# STM32F413 register map
File version: 1.9
CPU: CM4 r0p1, little endian, MPU, FPU, 4 interrupt priority bits
Registers are 32-bit, read-write, reset 0x0 unless marked. A register's access mark holds for its fields unless they carry their own. Offsets are from the block's base; [hi:lo] are bit positions; {n}, {i} and the like mark numbered series.

## EXTI — External interrupt/event controller
Base 0x40013C00
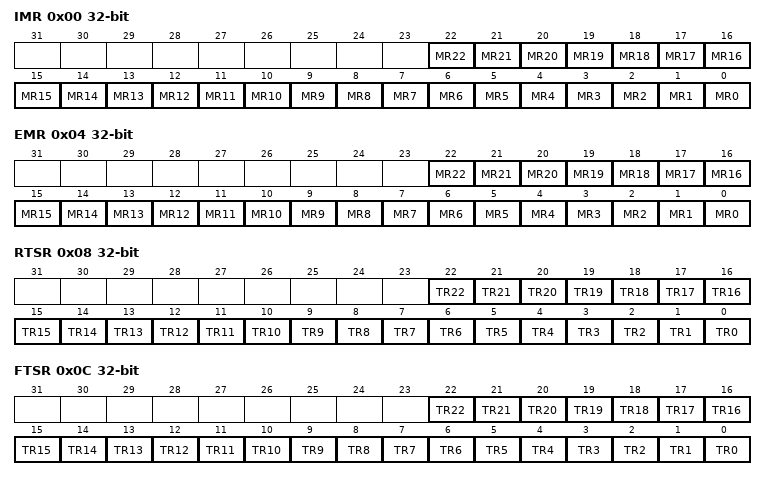
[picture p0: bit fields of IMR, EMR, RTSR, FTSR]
0x00 IMR — Interrupt mask register (EXTI_IMR)
  [n] MR{n} (n=0..22) — Interrupt Mask on line {n}
0x04 EMR — Event mask register (EXTI_EMR)
  [n] MR{n} (n=0..22) — Event Mask on line {n}
0x08 RTSR — Rising Trigger selection register (EXTI_RTSR)
  [n] TR{n} (n=0..22) — Rising trigger event configuration of line {n}
0x0C FTSR — Falling Trigger selection register (EXTI_FTSR)
  [n] TR{n} (n=0..22) — Falling trigger event configuration of line {n}
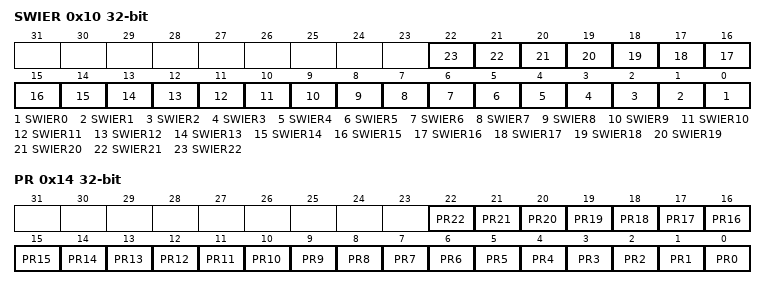
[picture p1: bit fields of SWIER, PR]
0x10 SWIER — Software interrupt event register (EXTI_SWIER)
  [n] SWIER{n} (n=0..22) — Software Interrupt on line {n}
0x14 PR — Pending register (EXTI_PR)
  [22] PR22 write-1-clears — Pending bit 22
  [21] PR21 write-1-clears — Pending bit 21
  [20] PR20 — Pending bit 20
  [19] PR19 — Pending bit 19
  [n] PR{n} write-1-clears (n=0..18) — Pending bit {n}

## FMPI2C — fast-mode Inter-integrated circuit
Base 0x40006000
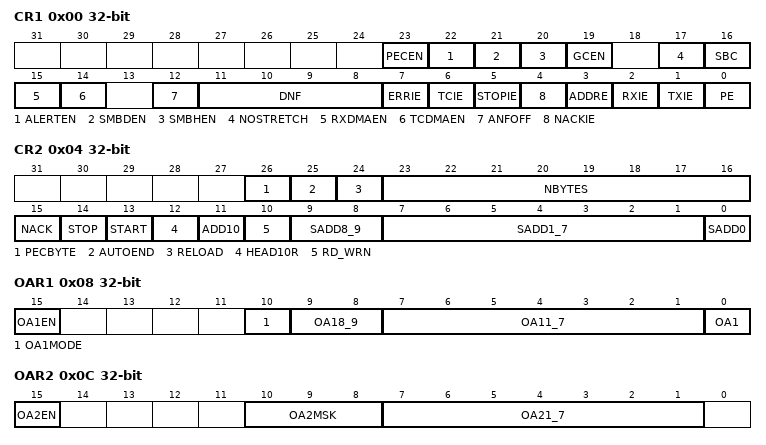
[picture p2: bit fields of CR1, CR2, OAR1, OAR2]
0x00 CR1 — Control register 1
  [23] PECEN
  [22] ALERTEN
  [21] SMBDEN
  [20] SMBHEN
  [19] GCEN
  [17] NOSTRETCH
  [16] SBC
  [15] RXDMAEN
  [14] TCDMAEN
  [12] ANFOFF
  [11:8] DNF
  [7] ERRIE
  [6] TCIE
  [5] STOPIE
  [4] NACKIE
  [3] ADDRE
  [2] RXIE
  [1] TXIE
  [0] PE — Peripheral enable
0x04 CR2 — Control register 2
  [26] PECBYTE — Packet error checking byte
  [25] AUTOEND — Automatic end mode
  [24] RELOAD — NBYTES reload mode
  [23:16] NBYTES — Number of bytes
  [15] NACK — NACK generation
  [14] STOP — Stop generation
  [13] START — Start generation
  [12] HEAD10R — 10-bit address header only read direction
  [11] ADD10 — 10-bit addressing mode
  [10] RD_WRN — Transfer direction
  [9:8] SADD8_9 — Slave address bit 8_9
  [7:1] SADD1_7 — Slave address bit 7_1
  [0] SADD0 — Slave address bit 0
0x08 OAR1 — Own address register 1
  [15] OA1EN, [10] OA1MODE, [9:8] OA18_9, [7:1] OA11_7, [0] OA1
0x0C OAR2 — Own address register 2
  [15] OA2EN, [10:8] OA2MSK, [7:1] OA21_7
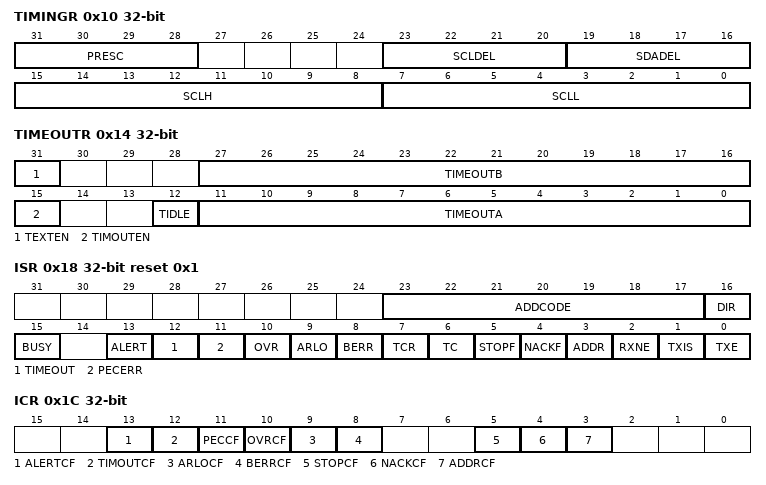
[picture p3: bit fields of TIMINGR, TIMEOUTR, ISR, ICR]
0x10 TIMINGR — Timing register
  [31:28] PRESC, [23:20] SCLDEL, [19:16] SDADEL, [15:8] SCLH, [7:0] SCLL
0x14 TIMEOUTR — Timeout register
  [31] TEXTEN, [27:16] TIMEOUTB, [15] TIMOUTEN, [12] TIDLE, [11:0] TIMEOUTA
0x18 ISR access per field reset 0x1 — Interrupt and Status register
  [23:17] ADDCODE ro, [16] DIR ro, [15] BUSY ro, [13] ALERT ro, [12] TIMEOUT ro, [11] PECERR ro, [10] OVR ro, [9] ARLO ro, [8] BERR ro, [7] TCR ro, [6] TC ro, [5] STOPF ro, [4] NACKF ro, [3] ADDR ro, [2] RXNE ro, [1] TXIS rw, [0] TXE rw
0x1C ICR wo — Interrupt clear register
  [13] ALERTCF — Alert flag clear
  [12] TIMOUTCF — Timeout detection flag clear
  [11] PECCF — PEC Error flag clear
  [10] OVRCF — Overrun/Underrun flag clear
  [9] ARLOCF — Arbitration Lost flag clear
  [8] BERRCF — Bus error flag clear
  [5] STOPCF — Stop detection flag clear
  [4] NACKCF — Not Acknowledge flag clear
  [3] ADDRCF — Address matched flag clear
0x20 PECR ro — PEC register
  [7:0] PEC
0x24 RXDR ro — Receive data register
  [7:0] RXDATA
0x28 TXDR — Transmit data register
  [7:0] TXDATA

## FLASH
Base 0x40023C00
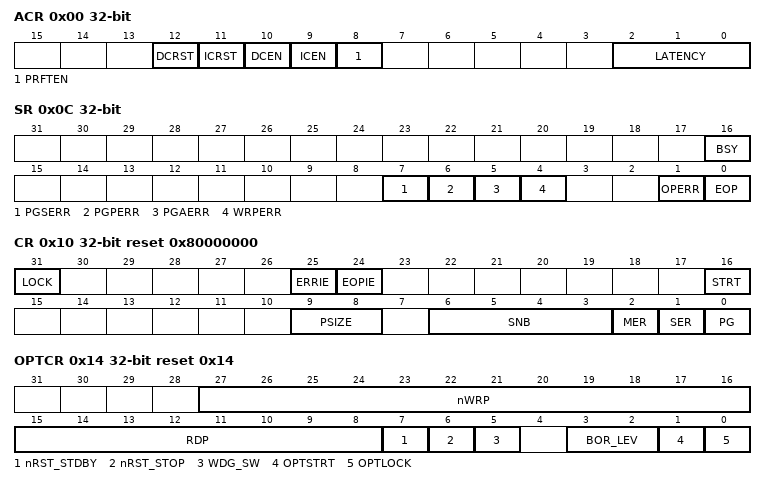
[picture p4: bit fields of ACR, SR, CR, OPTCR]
0x00 ACR access per field — Flash access control register
  [12] DCRST rw — Data cache reset
  [11] ICRST wo write-1-sets — Instruction cache reset
  [10] DCEN rw — Data cache enable
  [9] ICEN rw — Instruction cache enable
  [8] PRFTEN rw — Prefetch enable
  [2:0] LATENCY rw
0x04 KEYR wo — Flash key register
  [31:0] KEY — FPEC key
0x08 OPTKEYR wo — Flash option key register
  [31:0] OPTKEY — Option byte key
0x0C SR access per field — Status register
  [16] BSY ro — Busy
  [7] PGSERR rw write-1-clears — Programming sequence error
  [6] PGPERR rw write-1-clears — Programming parallelism error
  [5] PGAERR rw write-1-clears — Programming alignment error
  [4] WRPERR rw write-1-clears — Write protection error
  [1] OPERR rw write-1-clears — Operation error
  [0] EOP rw write-1-clears — End of operation
0x10 CR reset 0x80000000 — Control register
  [31] LOCK
  [25] ERRIE — Error interrupt enable
  [24] EOPIE — End of operation interrupt enable
  [16] STRT — Start
  [9:8] PSIZE — Program size
  [6:3] SNB — Sector number
  [2] MER — Mass Erase
  [1] SER — Sector Erase
  [0] PG — Programming
0x14 OPTCR reset 0x14 — Flash option control register
  [27:16] nWRP — Not write protect
  [15:8] RDP — Read protect
  [7] nRST_STDBY — nRST_STDBY User option bytes
  [6] nRST_STOP — nRST_STOP User option bytes
  [5] WDG_SW — WDG_SW User option bytes
  [3:2] BOR_LEV — BOR reset Level
  [1] OPTSTRT — Option start
  [0] OPTLOCK — Option lock
